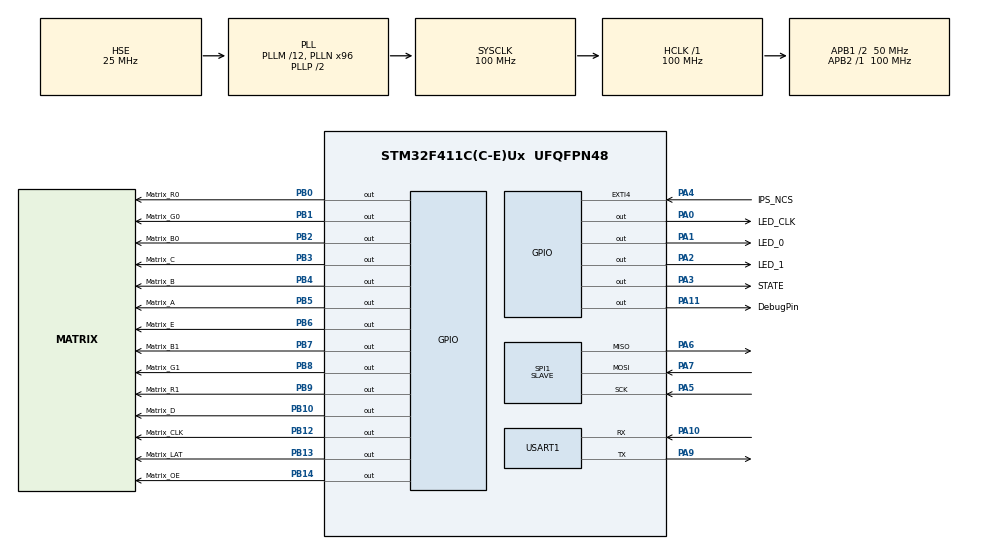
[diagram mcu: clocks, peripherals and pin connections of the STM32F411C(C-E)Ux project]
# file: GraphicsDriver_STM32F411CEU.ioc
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Dma.Request0=TIM1_CH1
Dma.Request1=SPI1_RX
Dma.SPI1_RX.1.Direction=DMA_PERIPH_TO_MEMORY
Dma.SPI1_RX.1.FIFOMode=DMA_FIFOMODE_DISABLE
Dma.SPI1_RX.1.Instance=DMA2_Stream0
Dma.SPI1_RX.1.MemDataAlignment=DMA_MDATAALIGN_BYTE
Dma.SPI1_RX.1.MemInc=DMA_MINC_ENABLE
Dma.SPI1_RX.1.Mode=DMA_NORMAL
Dma.SPI1_RX.1.PeriphDataAlignment=DMA_PDATAALIGN_BYTE
Dma.SPI1_RX.1.PeriphInc=DMA_PINC_DISABLE
Dma.SPI1_RX.1.Priority=DMA_PRIORITY_MEDIUM
Dma.TIM1_CH1.0.Direction=DMA_MEMORY_TO_PERIPH
Dma.TIM1_CH1.0.FIFOMode=DMA_FIFOMODE_DISABLE
Dma.TIM1_CH1.0.Instance=DMA2_Stream1
Dma.TIM1_CH1.0.MemDataAlignment=DMA_MDATAALIGN_HALFWORD
Dma.TIM1_CH1.0.MemInc=DMA_MINC_ENABLE
Dma.TIM1_CH1.0.Mode=DMA_NORMAL
Dma.TIM1_CH1.0.PeriphDataAlignment=DMA_PDATAALIGN_HALFWORD
Dma.TIM1_CH1.0.PeriphInc=DMA_PINC_DISABLE
Dma.TIM1_CH1.0.Priority=DMA_PRIORITY_LOW
Mcu.Family=STM32F4
Mcu.Name=STM32F411C(C-E)Ux
Mcu.Package=UFQFPN48
NVIC.DMA2_Stream0_IRQn=true\:0\:0\:false\:false\:true\:false\:true\:true
NVIC.DMA2_Stream1_IRQn=true\:0\:0\:false\:false\:true\:false\:true\:true
NVIC.EXTI4_IRQn=true\:0\:0\:false\:false\:true\:true\:true\:true
NVIC.PriorityGroup=NVIC_PRIORITYGROUP_4
NVIC.SPI1_IRQn=true\:0\:0\:false\:false\:true\:true\:true\:true
NVIC.TIM3_IRQn=true\:0\:0\:false\:false\:true\:true\:true\:true
PA0-WKUP.GPIO_Label=LED_CLK
PA0-WKUP.Signal=GPIO_Output
PA1.GPIO_Label=LED_0
PA1.Signal=GPIO_Output
PA10.Mode=Asynchronous
PA10.Signal=USART1_RX
PA11.GPIO_Label=DebugPin
PA11.Signal=GPIO_Output
PA13.Mode=Serial_Wire
PA13.Signal=SYS_JTMS-SWDIO
PA14.Mode=Serial_Wire
PA14.Signal=SYS_JTCK-SWCLK
PA2.GPIO_Label=LED_1
PA2.Signal=GPIO_Output
PA3.GPIO_Label=STATE
PA3.Signal=GPIO_Output
PA4.GPIO_Label=IPS_NCS
PA4.GPIO_ModeDefaultEXTI=GPIO_MODE_IT_RISING_FALLING
PA4.GPIO_PuPd=GPIO_PULLUP
PA4.Signal=GPXTI4
PA5.Mode=Full_Duplex_Slave
PA5.Signal=SPI1_SCK
PA6.Mode=Full_Duplex_Slave
PA6.Signal=SPI1_MISO
PA7.Mode=Full_Duplex_Slave
PA7.Signal=SPI1_MOSI
PA9.Mode=Asynchronous
PA9.Signal=USART1_TX
PB0.GPIO_Label=Matrix_R0
PB0.GPIO_Speed=GPIO_SPEED_FREQ_HIGH
PB0.Signal=GPIO_Output
PB1.GPIO_Label=Matrix_G0
PB1.GPIO_Speed=GPIO_SPEED_FREQ_HIGH
PB1.Signal=GPIO_Output
PB10.GPIO_Label=Matrix_D
PB10.GPIO_Speed=GPIO_SPEED_FREQ_HIGH
PB10.Signal=GPIO_Output
PB12.GPIO_Label=Matrix_CLK
PB12.GPIO_Speed=GPIO_SPEED_FREQ_HIGH
PB12.Signal=GPIO_Output
PB13.GPIO_Label=Matrix_LAT
PB13.GPIO_Speed=GPIO_SPEED_FREQ_HIGH
PB13.PinState=GPIO_PIN_SET
PB13.Signal=GPIO_Output
PB14.GPIO_Label=Matrix_OE
PB14.GPIO_Speed=GPIO_SPEED_FREQ_HIGH
PB14.Signal=GPIO_Output
PB2.GPIO_Label=Matrix_B0
PB2.GPIO_Speed=GPIO_SPEED_FREQ_HIGH
PB2.Signal=GPIO_Output
PB3.GPIO_Label=Matrix_C
PB3.GPIO_Speed=GPIO_SPEED_FREQ_HIGH
PB3.Signal=GPIO_Output
PB4.GPIO_Label=Matrix_B
PB4.GPIO_Speed=GPIO_SPEED_FREQ_HIGH
PB4.Signal=GPIO_Output
PB5.GPIO_Label=Matrix_A
PB5.GPIO_Speed=GPIO_SPEED_FREQ_HIGH
PB5.Signal=GPIO_Output
PB6.GPIO_Label=Matrix_E
PB6.GPIO_Speed=GPIO_SPEED_FREQ_HIGH
PB6.Signal=GPIO_Output
PB7.GPIO_Label=Matrix_B1
PB7.GPIO_Speed=GPIO_SPEED_FREQ_HIGH
PB7.Signal=GPIO_Output
PB8.GPIO_Label=Matrix_G1
PB8.GPIO_Speed=GPIO_SPEED_FREQ_HIGH
PB8.Signal=GPIO_Output
PB9.GPIO_Label=Matrix_R1
PB9.GPIO_Speed=GPIO_SPEED_FREQ_HIGH
PB9.Signal=GPIO_Output
PH0\ -\ OSC_IN.Mode=HSE-External-Oscillator
PH0\ -\ OSC_IN.Signal=RCC_OSC_IN
PH1\ -\ OSC_OUT.Mode=HSE-External-Oscillator
PH1\ -\ OSC_OUT.Signal=RCC_OSC_OUT
ProjectManager.HeapSize=0x8000
ProjectManager.StackSize=0x400
ProjectManager.TargetToolchain=STM32CubeIDE
RCC.48MHZClocksFreq_Value=50000000
RCC.AHBFreq_Value=100000000
RCC.APB1CLKDivider=RCC_HCLK_DIV2
RCC.APB1Freq_Value=50000000
RCC.APB1TimFreq_Value=100000000
RCC.APB2Freq_Value=100000000
RCC.APB2TimFreq_Value=100000000
RCC.CortexFreq_Value=100000000
RCC.HCLKFreq_Value=100000000
RCC.HSE_VALUE=25000000
RCC.HSI_VALUE=16000000
RCC.LSE_VALUE=32768
RCC.PLLM=12
RCC.PLLN=96
RCC.PLLSourceVirtual=RCC_PLLSOURCE_HSE
RCC.SYSCLKFreq_VALUE=100000000
RCC.SYSCLKSource=RCC_SYSCLKSOURCE_PLLCLK
RCC.VCOOutputFreq_Value=200000000
SPI1.Direction=SPI_DIRECTION_2LINES
SPI1.Mode=SPI_MODE_SLAVE
SPI1.VirtualType=VM_SLAVE
TIM1.Channel-PWM\ Generation1\ No\ Output=TIM_CHANNEL_1
TIM1.Period=1
TIM1.Pulse-PWM\ Generation1\ No\ Output=1
TIM3.Channel-PWM\ Generation1\ No\ Output=TIM_CHANNEL_1
TIM3.Period=10
TIM3.Prescaler=200
TIM3.Pulse-PWM\ Generation1\ No\ Output=4
USART1.VirtualMode=VM_ASYNC
VP_TIM1_VS_ClockSourceINT.Mode=Internal
VP_TIM1_VS_no_output1.Mode=PWM Generation1 No Output
VP_TIM3_VS_OPM.Mode=OPM_bit
VP_TIM3_VS_no_output1.Mode=PWM Generation1 No Output
board=custom

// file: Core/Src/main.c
/* USER CODE BEGIN Header */
/**
  ******************************************************************************
  * @file           : main.c
  * @brief          : Main program body
  ******************************************************************************
  * @attention
  *
  * <h2><center>&copy; Copyright (c) 2020 STMicroelectronics.
  * All rights reserved.</center></h2>
  *
  * This software component is licensed by ST under BSD 3-Clause license,
  * the "License"; You may not use this file except in compliance with the
  * License. You may obtain a copy of the License at:
  *                        opensource.org/licenses/BSD-3-Clause
  *
  ******************************************************************************
  */
/* USER CODE END Header */
#include "main.h"

/* USER CODE BEGIN Includes */

#include "cpp_main.h"

/* USER CODE END Includes */

SPI_HandleTypeDef hspi1;
DMA_HandleTypeDef hdma_spi1_rx;

TIM_HandleTypeDef htim1;
TIM_HandleTypeDef htim3;
DMA_HandleTypeDef hdma_tim1_ch1;

UART_HandleTypeDef huart1;

void SystemClock_Config(void);
static void MX_GPIO_Init(void);
static void MX_DMA_Init(void);
static void MX_TIM1_Init(void);
static void MX_USART1_UART_Init(void);
static void MX_SPI1_Init(void);
static void MX_TIM3_Init(void);

int main(void)
{
  /* USER CODE BEGIN 1 */

	uint32_t reset_reason = RCC->CSR;

  /* USER CODE END 1 */

  /* MCU Configuration--------------------------------------------------------*/

  /* Reset of all peripherals, Initializes the Flash interface and the Systick. */
  HAL_Init();

  /* Configure the system clock */
  SystemClock_Config();

  /* Initialize all configured peripherals */
  MX_GPIO_Init();
  MX_DMA_Init();
  MX_TIM1_Init();
  MX_USART1_UART_Init();
  MX_SPI1_Init();
  MX_TIM3_Init();
  /* USER CODE BEGIN 2 */

  cpp_main();

  /* USER CODE END 2 */

  /* Infinite loop */
  while (1)
  {

  }
}

void SystemClock_Config(void)
{
  RCC_OscInitTypeDef RCC_OscInitStruct = {0};
  RCC_ClkInitTypeDef RCC_ClkInitStruct = {0};

  /** Configure the main internal regulator output voltage
  */
  __HAL_RCC_PWR_CLK_ENABLE();
  __HAL_PWR_VOLTAGESCALING_CONFIG(PWR_REGULATOR_VOLTAGE_SCALE1);

  /** Initializes the RCC Oscillators according to the specified parameters
  * in the RCC_OscInitTypeDef structure.
  */
  RCC_OscInitStruct.OscillatorType = RCC_OSCILLATORTYPE_HSE;
  RCC_OscInitStruct.HSEState = RCC_HSE_ON;
  RCC_OscInitStruct.PLL.PLLState = RCC_PLL_ON;
  RCC_OscInitStruct.PLL.PLLSource = RCC_PLLSOURCE_HSE;
  RCC_OscInitStruct.PLL.PLLM = 12;
  RCC_OscInitStruct.PLL.PLLN = 96;
  RCC_OscInitStruct.PLL.PLLP = RCC_PLLP_DIV2;
  RCC_OscInitStruct.PLL.PLLQ = 4;
  if (HAL_RCC_OscConfig(&RCC_OscInitStruct) != HAL_OK)
  {
    Error_Handler();
  }

  /** Initializes the CPU, AHB and APB buses clocks
  */
  RCC_ClkInitStruct.ClockType = RCC_CLOCKTYPE_HCLK|RCC_CLOCKTYPE_SYSCLK
                              |RCC_CLOCKTYPE_PCLK1|RCC_CLOCKTYPE_PCLK2;
  RCC_ClkInitStruct.SYSCLKSource = RCC_SYSCLKSOURCE_PLLCLK;
  RCC_ClkInitStruct.AHBCLKDivider = RCC_SYSCLK_DIV1;
  RCC_ClkInitStruct.APB1CLKDivider = RCC_HCLK_DIV2;
  RCC_ClkInitStruct.APB2CLKDivider = RCC_HCLK_DIV1;

  if (HAL_RCC_ClockConfig(&RCC_ClkInitStruct, FLASH_LATENCY_3) != HAL_OK)
  {
    Error_Handler();
  }
}

static void MX_SPI1_Init(void)
{

  /* SPI1 parameter configuration*/
  hspi1.Instance = SPI1;
  hspi1.Init.Mode = SPI_MODE_SLAVE;
  hspi1.Init.Direction = SPI_DIRECTION_2LINES;
  hspi1.Init.DataSize = SPI_DATASIZE_8BIT;
  hspi1.Init.CLKPolarity = SPI_POLARITY_LOW;
  hspi1.Init.CLKPhase = SPI_PHASE_1EDGE;
  hspi1.Init.NSS = SPI_NSS_SOFT;
  hspi1.Init.FirstBit = SPI_FIRSTBIT_MSB;
  hspi1.Init.TIMode = SPI_TIMODE_DISABLE;
  hspi1.Init.CRCCalculation = SPI_CRCCALCULATION_DISABLE;
  hspi1.Init.CRCPolynomial = 10;
  if (HAL_SPI_Init(&hspi1) != HAL_OK)
  {
    Error_Handler();
  }

}

static void MX_TIM1_Init(void)
{

  TIM_ClockConfigTypeDef sClockSourceConfig = {0};
  TIM_MasterConfigTypeDef sMasterConfig = {0};
  TIM_OC_InitTypeDef sConfigOC = {0};
  TIM_BreakDeadTimeConfigTypeDef sBreakDeadTimeConfig = {0};

  htim1.Instance = TIM1;
  htim1.Init.Prescaler = 0;
  htim1.Init.CounterMode = TIM_COUNTERMODE_UP;
  htim1.Init.Period = 1;
  htim1.Init.ClockDivision = TIM_CLOCKDIVISION_DIV1;
  htim1.Init.RepetitionCounter = 0;
  htim1.Init.AutoReloadPreload = TIM_AUTORELOAD_PRELOAD_DISABLE;
  if (HAL_TIM_Base_Init(&htim1) != HAL_OK)
  {
    Error_Handler();
  }
  sClockSourceConfig.ClockSource = TIM_CLOCKSOURCE_INTERNAL;
  if (HAL_TIM_ConfigClockSource(&htim1, &sClockSourceConfig) != HAL_OK)
  {
    Error_Handler();
  }
  if (HAL_TIM_PWM_Init(&htim1) != HAL_OK)
  {
    Error_Handler();
  }
  sMasterConfig.MasterOutputTrigger = TIM_TRGO_RESET;
  sMasterConfig.MasterSlaveMode = TIM_MASTERSLAVEMODE_DISABLE;
  if (HAL_TIMEx_MasterConfigSynchronization(&htim1, &sMasterConfig) != HAL_OK)
  {
    Error_Handler();
  }
  sConfigOC.OCMode = TIM_OCMODE_PWM1;
  sConfigOC.Pulse = 1;
  sConfigOC.OCPolarity = TIM_OCPOLARITY_HIGH;
  sConfigOC.OCNPolarity = TIM_OCNPOLARITY_HIGH;
  sConfigOC.OCFastMode = TIM_OCFAST_DISABLE;
  sConfigOC.OCIdleState = TIM_OCIDLESTATE_RESET;
  sConfigOC.OCNIdleState = TIM_OCNIDLESTATE_RESET;
  if (HAL_TIM_PWM_ConfigChannel(&htim1, &sConfigOC, TIM_CHANNEL_1) != HAL_OK)
  {
    Error_Handler();
  }
  sBreakDeadTimeConfig.OffStateRunMode = TIM_OSSR_DISABLE;
  sBreakDeadTimeConfig.OffStateIDLEMode = TIM_OSSI_DISABLE;
  sBreakDeadTimeConfig.LockLevel = TIM_LOCKLEVEL_OFF;
  sBreakDeadTimeConfig.DeadTime = 0;
  sBreakDeadTimeConfig.BreakState = TIM_BREAK_DISABLE;
  sBreakDeadTimeConfig.BreakPolarity = TIM_BREAKPOLARITY_HIGH;
  sBreakDeadTimeConfig.AutomaticOutput = TIM_AUTOMATICOUTPUT_DISABLE;
  if (HAL_TIMEx_ConfigBreakDeadTime(&htim1, &sBreakDeadTimeConfig) != HAL_OK)
  {
    Error_Handler();
  }

}

static void MX_TIM3_Init(void)
{

  TIM_MasterConfigTypeDef sMasterConfig = {0};
  TIM_OC_InitTypeDef sConfigOC = {0};

  htim3.Instance = TIM3;
  htim3.Init.Prescaler = 200;
  htim3.Init.CounterMode = TIM_COUNTERMODE_UP;
  htim3.Init.Period = 10;
  htim3.Init.ClockDivision = TIM_CLOCKDIVISION_DIV1;
  htim3.Init.AutoReloadPreload = TIM_AUTORELOAD_PRELOAD_DISABLE;
  if (HAL_TIM_PWM_Init(&htim3) != HAL_OK)
  {
    Error_Handler();
  }
  if (HAL_TIM_OnePulse_Init(&htim3, TIM_OPMODE_SINGLE) != HAL_OK)
  {
    Error_Handler();
  }
  sMasterConfig.MasterOutputTrigger = TIM_TRGO_RESET;
  sMasterConfig.MasterSlaveMode = TIM_MASTERSLAVEMODE_DISABLE;
  if (HAL_TIMEx_MasterConfigSynchronization(&htim3, &sMasterConfig) != HAL_OK)
  {
    Error_Handler();
  }
  sConfigOC.OCMode = TIM_OCMODE_PWM1;
  sConfigOC.Pulse = 4;
  sConfigOC.OCPolarity = TIM_OCPOLARITY_HIGH;
  sConfigOC.OCFastMode = TIM_OCFAST_DISABLE;
  if (HAL_TIM_PWM_ConfigChannel(&htim3, &sConfigOC, TIM_CHANNEL_1) != HAL_OK)
  {
    Error_Handler();
  }

}

static void MX_USART1_UART_Init(void)
{

  huart1.Instance = USART1;
  huart1.Init.BaudRate = 115200;
  huart1.Init.WordLength = UART_WORDLENGTH_8B;
  huart1.Init.StopBits = UART_STOPBITS_1;
  huart1.Init.Parity = UART_PARITY_NONE;
  huart1.Init.Mode = UART_MODE_TX_RX;
  huart1.Init.HwFlowCtl = UART_HWCONTROL_NONE;
  huart1.Init.OverSampling = UART_OVERSAMPLING_16;
  if (HAL_UART_Init(&huart1) != HAL_OK)
  {
    Error_Handler();
  }

}

static void MX_DMA_Init(void)
{

  /* DMA controller clock enable */
  __HAL_RCC_DMA2_CLK_ENABLE();

  /* DMA interrupt init */
  /* DMA2_Stream0_IRQn interrupt configuration */
  HAL_NVIC_SetPriority(DMA2_Stream0_IRQn, 0, 0);
  HAL_NVIC_EnableIRQ(DMA2_Stream0_IRQn);
  /* DMA2_Stream1_IRQn interrupt configuration */
  HAL_NVIC_SetPriority(DMA2_Stream1_IRQn, 0, 0);
  HAL_NVIC_EnableIRQ(DMA2_Stream1_IRQn);

}

static void MX_GPIO_Init(void)
{
  GPIO_InitTypeDef GPIO_InitStruct = {0};

  /* GPIO Ports Clock Enable */
  __HAL_RCC_GPIOH_CLK_ENABLE();
  __HAL_RCC_GPIOA_CLK_ENABLE();
  __HAL_RCC_GPIOB_CLK_ENABLE();

  /*Configure GPIO pin Output Level */
  HAL_GPIO_WritePin(GPIOA, LED_CLK_Pin|LED_0_Pin|LED_1_Pin|STATE_Pin
                          |DebugPin_Pin, GPIO_PIN_RESET);

  /*Configure GPIO pin Output Level */
  HAL_GPIO_WritePin(GPIOB, Matrix_R0_Pin|Matrix_G0_Pin|Matrix_B0_Pin|Matrix_D_Pin
                          |Matrix_CLK_Pin|Matrix_OE_Pin|Matrix_C_Pin|Matrix_B_Pin
                          |Matrix_A_Pin|Matrix_E_Pin|Matrix_B1_Pin|Matrix_G1_Pin
                          |Matrix_R1_Pin, GPIO_PIN_RESET);

  /*Configure GPIO pin Output Level */
  HAL_GPIO_WritePin(Matrix_LAT_GPIO_Port, Matrix_LAT_Pin, GPIO_PIN_SET);

  /*Configure GPIO pins : LED_CLK_Pin LED_0_Pin LED_1_Pin STATE_Pin
                           DebugPin_Pin */
  GPIO_InitStruct.Pin = LED_CLK_Pin|LED_0_Pin|LED_1_Pin|STATE_Pin
                          |DebugPin_Pin;
  GPIO_InitStruct.Mode = GPIO_MODE_OUTPUT_PP;
  GPIO_InitStruct.Pull = GPIO_NOPULL;
  GPIO_InitStruct.Speed = GPIO_SPEED_FREQ_LOW;
  HAL_GPIO_Init(GPIOA, &GPIO_InitStruct);

  /*Configure GPIO pin : IPS_NCS_Pin */
  GPIO_InitStruct.Pin = IPS_NCS_Pin;
  GPIO_InitStruct.Mode = GPIO_MODE_IT_RISING_FALLING;
  GPIO_InitStruct.Pull = GPIO_PULLUP;
  HAL_GPIO_Init(IPS_NCS_GPIO_Port, &GPIO_InitStruct);

  /*Configure GPIO pins : Matrix_R0_Pin Matrix_G0_Pin Matrix_B0_Pin Matrix_D_Pin
                           Matrix_CLK_Pin Matrix_LAT_Pin Matrix_OE_Pin Matrix_C_Pin
                           Matrix_B_Pin Matrix_A_Pin Matrix_E_Pin Matrix_B1_Pin
                           Matrix_G1_Pin Matrix_R1_Pin */
  GPIO_InitStruct.Pin = Matrix_R0_Pin|Matrix_G0_Pin|Matrix_B0_Pin|Matrix_D_Pin
                          |Matrix_CLK_Pin|Matrix_LAT_Pin|Matrix_OE_Pin|Matrix_C_Pin
                          |Matrix_B_Pin|Matrix_A_Pin|Matrix_E_Pin|Matrix_B1_Pin
                          |Matrix_G1_Pin|Matrix_R1_Pin;
  GPIO_InitStruct.Mode = GPIO_MODE_OUTPUT_PP;
  GPIO_InitStruct.Pull = GPIO_NOPULL;
  GPIO_InitStruct.Speed = GPIO_SPEED_FREQ_HIGH;
  HAL_GPIO_Init(GPIOB, &GPIO_InitStruct);

  /* EXTI interrupt init*/
  HAL_NVIC_SetPriority(EXTI4_IRQn, 0, 0);
  HAL_NVIC_EnableIRQ(EXTI4_IRQn);

}

void Error_Handler(void)
{
}
